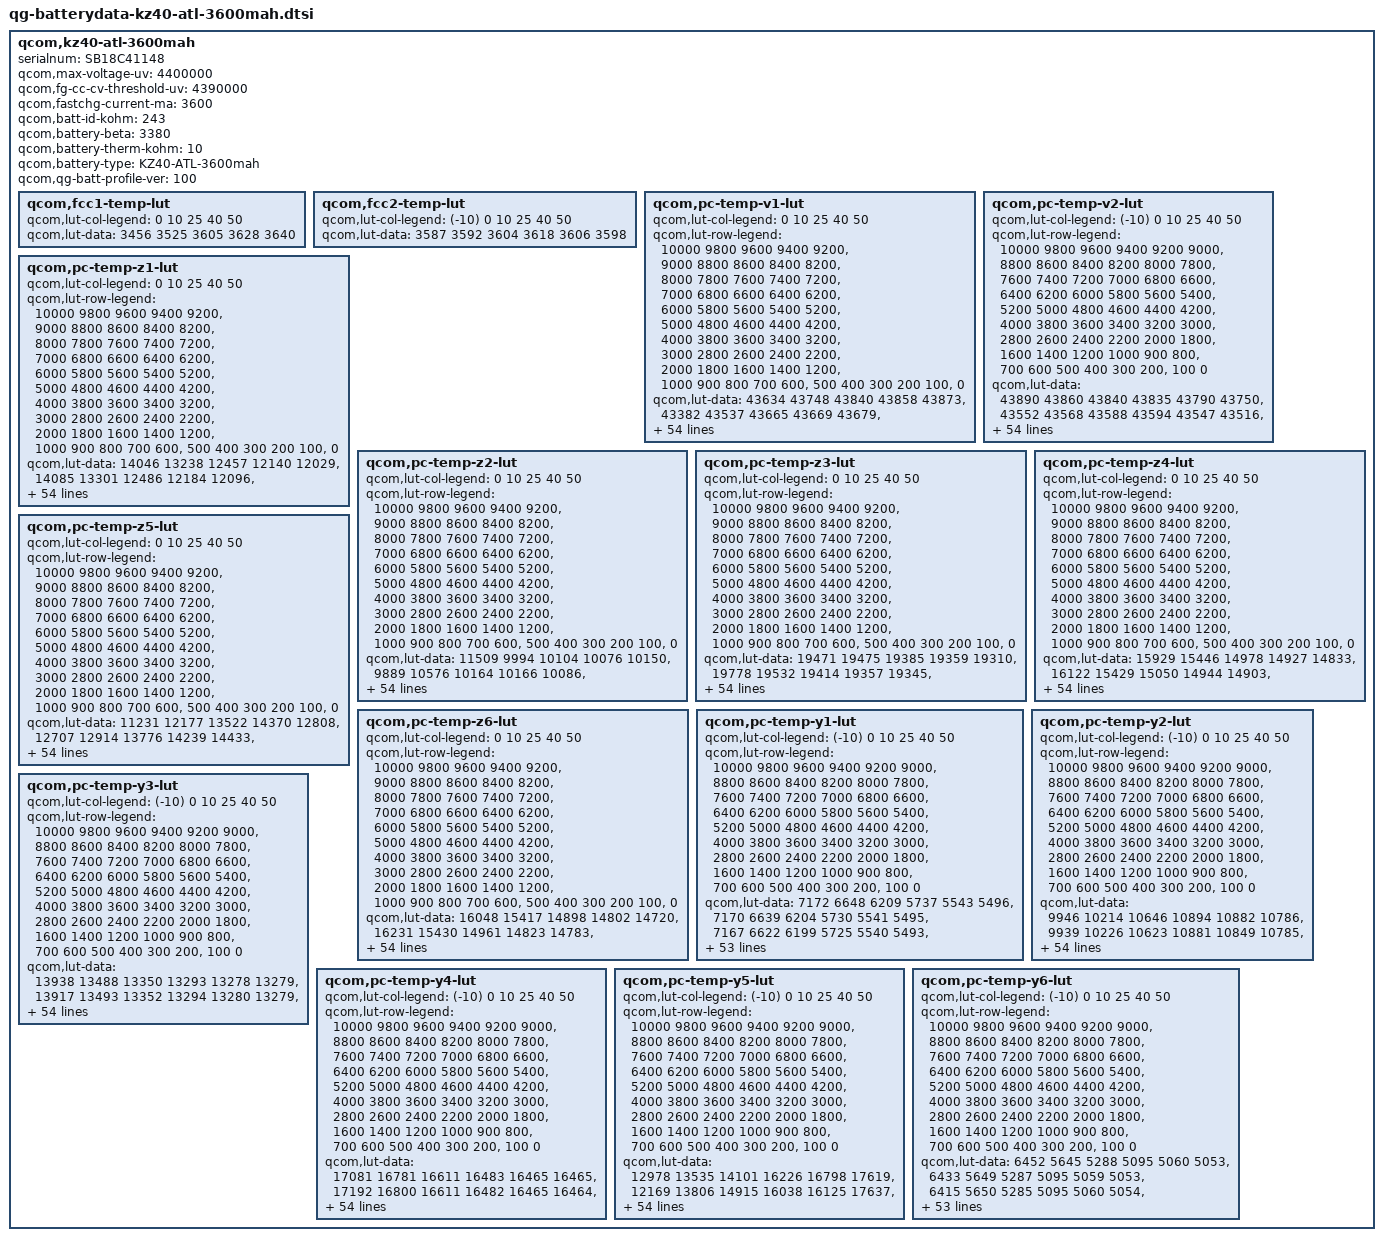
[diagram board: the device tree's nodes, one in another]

qcom,kz40-atl-3600mah {
    /* 3673330_Lenovo_KZ40moto_3600mAh_averaged_MasterSlave_Oct1st2018 */
    serialnum = "SB18C41148";
    qcom,max-voltage-uv = <4400000>;
    qcom,fg-cc-cv-threshold-uv = <4390000>;
    qcom,fastchg-current-ma = <3600>;
    qcom,batt-id-kohm = <243>;
    qcom,battery-beta = <3380>;
    qcom,battery-therm-kohm = <10>;
    qcom,battery-type = "KZ40-ATL-3600mah";
    qcom,qg-batt-profile-ver = <100>;

	qcom,fcc1-temp-lut {
		qcom,lut-col-legend = <0 10 25 40 50>;
		qcom,lut-data = <3456 3525 3605 3628 3640>;
	};

	qcom,fcc2-temp-lut {
		qcom,lut-col-legend = <(-10) 0 10 25 40 50>;
		qcom,lut-data = <3587 3592 3604 3618 3606 3598>;
	};

	qcom,pc-temp-v1-lut {
		qcom,lut-col-legend = <0 10 25 40 50>;
		qcom,lut-row-legend = <10000 9800 9600 9400 9200>,
			<9000 8800 8600 8400 8200>,
			<8000 7800 7600 7400 7200>,
			<7000 6800 6600 6400 6200>,
			<6000 5800 5600 5400 5200>,
			<5000 4800 4600 4400 4200>,
			<4000 3800 3600 3400 3200>,
			<3000 2800 2600 2400 2200>,
			<2000 1800 1600 1400 1200>,
			<1000 900 800 700 600>,
			<500 400 300 200 100>,
			<0>;
		qcom,lut-data = <43634 43748 43840 43858 43873>,
			<43382 43537 43665 43669 43679>,
			<43141 43311 43435 43460 43475>,
			<42905 43068 43204 43242 43263>,
			<42672 42824 42969 43015 43040>,
			<42441 42589 42731 42781 42809>,
			<42216 42357 42497 42548 42578>,
			<41995 42130 42264 42315 42346>,
			<41780 41908 42034 42083 42115>,
			<41569 41690 41806 41853 41885>,
			<41362 41475 41581 41625 41657>,
			<41163 41265 41364 41404 41434>,
			<40981 41065 41150 41186 41214>,
			<40802 40884 40943 40976 41002>,
			<40589 40699 40741 40772 40794>,
			<40322 40482 40542 40574 40593>,
			<40078 40240 40336 40378 40397>,
			<39909 40034 40134 40186 40208>,
			<39771 39880 39960 40007 40028>,
			<39637 39740 39822 39852 39867>,
			<39506 39583 39664 39689 39703>,
			<39376 39417 39408 39455 39485>,
			<39237 39237 39111 39166 39213>,
			<39090 39012 38924 38965 39004>,
			<38944 38791 38806 38845 38875>,
			<38798 38665 38706 38746 38766>,
			<38659 38585 38612 38643 38655>,
			<38551 38519 38526 38543 38548>,
			<38464 38456 38444 38450 38450>,
			<38394 38398 38366 38362 38359>,
			<38339 38343 38294 38281 38275>,
			<38294 38292 38227 38208 38199>,
			<38254 38243 38167 38141 38129>,
			<38219 38200 38115 38079 38062>,
			<38187 38160 38072 38023 38001>,
			<38155 38121 38030 37970 37940>,
			<38126 38085 37987 37917 37878>,
			<38090 38044 37943 37865 37814>,
			<38032 37979 37880 37797 37738>,
			<37953 37886 37788 37705 37644>,
			<37858 37783 37683 37601 37538>,
			<37736 37667 37571 37489 37423>,
			<37598 37534 37444 37362 37294>,
			<37442 37372 37288 37207 37138>,
			<37305 37234 37152 37073 37008>,
			<37216 37151 37066 36988 36932>,
			<37189 37126 37043 36966 36907>,
			<37170 37106 37028 36947 36889>,
			<37146 37085 37009 36928 36869>,
			<37095 37039 36958 36869 36802>,
			<36867 36801 36707 36601 36518>,
			<36419 36360 36271 36165 36083>,
			<35843 35787 35696 35594 35515>,
			<35057 35003 34912 34816 34743>,
			<33812 33769 33688 33612 33552>,
			<30000 30000 30000 30000 30000>;
	};

	qcom,pc-temp-v2-lut {
		qcom,lut-col-legend = <(-10) 0 10 25 40 50>;
		qcom,lut-row-legend = <10000 9800 9600 9400 9200 9000>,
			<8800 8600 8400 8200 8000 7800>,
			<7600 7400 7200 7000 6800 6600>,
			<6400 6200 6000 5800 5600 5400>,
			<5200 5000 4800 4600 4400 4200>,
			<4000 3800 3600 3400 3200 3000>,
			<2800 2600 2400 2200 2000 1800>,
			<1600 1400 1200 1000 900 800>,
			<700 600 500 400 300 200>,
			<100 0>;
		qcom,lut-data = <43890 43860 43840 43835 43790 43750>,
			<43552 43568 43588 43594 43547 43516>,
			<43236 43289 43339 43355 43307 43283>,
			<42942 43022 43093 43117 43071 43052>,
			<42668 42768 42850 42881 42840 42824>,
			<42413 42520 42609 42646 42609 42594>,
			<42184 42271 42369 42410 42377 42363>,
			<41967 42029 42132 42175 42144 42131>,
			<41727 41803 41902 41943 41914 41902>,
			<41456 41592 41676 41714 41686 41674>,
			<41228 41385 41456 41487 41461 41449>,
			<41091 41180 41241 41265 41239 41229>,
			<40974 40975 41031 41047 41021 41011>,
			<40768 40773 40829 40840 40813 40802>,
			<40397 40576 40635 40641 40613 40597>,
			<40032 40355 40433 40442 40417 40400>,
			<39765 40054 40207 40230 40217 40209>,
			<39532 39727 39970 40022 40022 40025>,
			<39328 39495 39741 39847 39847 39850>,
			<39149 39330 39515 39697 39693 39687>,
			<38983 39173 39304 39523 39519 39508>,
			<38818 38999 39111 39274 39277 39272>,
			<38662 38828 38935 39016 39021 39022>,
			<38525 38679 38783 38833 38837 38839>,
			<38401 38550 38649 38690 38697 38700>,
			<38296 38427 38527 38566 38574 38577>,
			<38215 38297 38416 38454 38462 38464>,
			<38148 38175 38313 38353 38361 38361>,
			<38087 38088 38219 38260 38268 38266>,
			<38033 38023 38132 38173 38183 38178>,
			<37982 37971 38052 38095 38105 38098>,
			<37932 37926 37974 38023 38036 38027>,
			<37883 37887 37904 37957 37970 37960>,
			<37834 37849 37847 37894 37902 37886>,
			<37786 37815 37800 37837 37833 37807>,
			<37737 37776 37756 37774 37755 37718>,
			<37683 37732 37714 37705 37659 37612>,
			<37624 37682 37671 37631 37555 37496>,
			<37555 37620 37615 37555 37468 37401>,
			<37474 37539 37543 37478 37390 37322>,
			<37387 37447 37460 37394 37308 37239>,
			<37298 37346 37356 37297 37213 37141>,
			<37207 37233 37236 37185 37105 37031>,
			<37117 37105 37095 37046 36971 36894>,
			<37030 36979 36972 36932 36865 36800>,
			<36940 36878 36904 36889 36824 36766>,
			<36891 36836 36880 36874 36812 36753>,
			<36839 36795 36854 36855 36799 36738>,
			<36777 36741 36813 36824 36770 36701>,
			<36664 36650 36717 36733 36678 36572>,
			<36432 36436 36427 36431 36372 36206>,
			<36007 35998 35916 35930 35889 35705>,
			<35381 35381 35246 35291 35261 35045>,
			<34489 34519 34318 34410 34410 34138>,
			<33116 33163 32958 33135 33145 32881>,
			<27998 27622 27822 27928 28920 29976>;
	};

	qcom,pc-temp-z1-lut {
		qcom,lut-col-legend = <0 10 25 40 50>;
		qcom,lut-row-legend = <10000 9800 9600 9400 9200>,
			<9000 8800 8600 8400 8200>,
			<8000 7800 7600 7400 7200>,
			<7000 6800 6600 6400 6200>,
			<6000 5800 5600 5400 5200>,
			<5000 4800 4600 4400 4200>,
			<4000 3800 3600 3400 3200>,
			<3000 2800 2600 2400 2200>,
			<2000 1800 1600 1400 1200>,
			<1000 900 800 700 600>,
			<500 400 300 200 100>,
			<0>;
		qcom,lut-data = <14046 13238 12457 12140 12029>,
			<14085 13301 12486 12184 12096>,
			<14085 13314 12512 12205 12116>,
			<14086 13298 12517 12212 12126>,
			<14090 13281 12508 12212 12130>,
			<14097 13264 12498 12212 12133>,
			<14097 13239 12489 12212 12136>,
			<14074 13223 12481 12211 12139>,
			<14043 13210 12477 12211 12142>,
			<14030 13200 12475 12213 12145>,
			<14023 13197 12474 12215 12148>,
			<14012 13194 12474 12216 12148>,
			<13980 13190 12474 12216 12149>,
			<13935 13166 12473 12216 12149>,
			<13904 13142 12470 12215 12149>,
			<13874 13133 12467 12214 12149>,
			<13852 13127 12465 12214 12149>,
			<13847 13125 12463 12214 12150>,
			<13852 13132 12463 12215 12151>,
			<13856 13140 12468 12216 12152>,
			<13861 13146 12473 12218 12153>,
			<13869 13154 12477 12219 12154>,
			<13884 13159 12480 12220 12154>,
			<13913 13162 12483 12221 12155>,
			<13931 13164 12486 12223 12157>,
			<13930 13167 12490 12227 12160>,
			<13924 13175 12496 12230 12163>,
			<13923 13182 12504 12234 12167>,
			<13936 13187 12510 12238 12170>,
			<13946 13192 12516 12243 12174>,
			<13946 13197 12522 12248 12177>,
			<13945 13205 12528 12252 12181>,
			<13944 13212 12535 12257 12184>,
			<13939 13218 12542 12261 12187>,
			<13934 13225 12550 12266 12192>,
			<13942 13233 12558 12271 12196>,
			<13968 13247 12565 12275 12198>,
			<13993 13262 12571 12278 12200>,
			<14011 13272 12579 12282 12203>,
			<14026 13281 12588 12286 12206>,
			<14032 13291 12596 12290 12210>,
			<14035 13310 12602 12294 12213>,
			<14038 13324 12608 12297 12216>,
			<14046 13334 12617 12300 12218>,
			<14056 13344 12627 12305 12220>,
			<14068 13349 12630 12307 12221>,
			<14071 13328 12628 12308 12222>,
			<14055 13328 12632 12309 12222>,
			<14053 13315 12632 12311 12225>,
			<14062 13334 12643 12315 12228>,
			<14105 13349 12649 12322 12233>,
			<14094 13376 12663 12329 12241>,
			<14117 13405 12676 12341 12251>,
			<14150 13452 12706 12357 12266>,
			<14150 13452 12706 12357 12266>,
			<14150 13452 12706 12357 12266>;
	};

	qcom,pc-temp-z2-lut {
		qcom,lut-col-legend = <0 10 25 40 50>;
		qcom,lut-row-legend = <10000 9800 9600 9400 9200>,
			<9000 8800 8600 8400 8200>,
			<8000 7800 7600 7400 7200>,
			<7000 6800 6600 6400 6200>,
			<6000 5800 5600 5400 5200>,
			<5000 4800 4600 4400 4200>,
			<4000 3800 3600 3400 3200>,
			<3000 2800 2600 2400 2200>,
			<2000 1800 1600 1400 1200>,
			<1000 900 800 700 600>,
			<500 400 300 200 100>,
			<0>;
		qcom,lut-data = <11509 9994 10104 10076 10150>,
			<9889 10576 10164 10166 10086>,
			<9883 10595 10194 10227 10081>,
			<9880 10236 10199 10251 10085>,
			<9876 9982 10188 10247 10122>,
			<9871 9963 10171 10239 10180>,
			<9870 9946 10150 10223 10194>,
			<9872 9934 10125 10190 10176>,
			<9874 9925 10112 10169 10149>,
			<9873 9919 10101 10163 10078>,
			<9869 9917 10096 10157 9990>,
			<9866 9915 10099 10128 9978>,
			<9876 9921 10105 10056 9995>,
			<9895 10005 10110 10024 10011>,
			<9890 10088 10117 10031 10021>,
			<9847 10069 10121 10039 10030>,
			<9812 10001 10123 10037 10035>,
			<9817 9972 10127 10027 10043>,
			<9834 9987 10128 10024 10051>,
			<9847 10008 10126 10045 10071>,
			<9856 10023 10123 10070 10094>,
			<9862 10037 10132 10076 10100>,
			<9866 10043 10145 10074 10101>,
			<9868 10039 10140 10074 10104>,
			<9870 10031 10111 10083 10125>,
			<9878 10032 10092 10092 10154>,
			<9890 10040 10119 10101 10180>,
			<9897 10047 10170 10121 10207>,
			<9902 10047 10191 10127 10212>,
			<9906 10045 10204 10120 10134>,
			<9910 10045 10209 10110 10049>,
			<9915 10049 10206 10084 10021>,
			<9919 10053 10201 10043 9986>,
			<9923 10056 10198 10031 9976>,
			<9928 10061 10195 10042 10008>,
			<9934 10065 10196 10060 10051>,
			<9942 10070 10208 10087 10088>,
			<9950 10076 10229 10125 10125>,
			<9957 10084 10251 10152 10157>,
			<9965 10095 10279 10171 10190>,
			<9970 10099 10295 10188 10209>,
			<9975 10098 10297 10209 10202>,
			<9983 10098 10298 10223 10189>,
			<10010 10106 10301 10217 10179>,
			<10191 10192 10315 10222 10174>,
			<10264 10251 10307 10203 10171>,
			<10287 10272 10283 10226 10158>,
			<10317 10301 10284 10238 10165>,
			<10318 10339 10291 10236 10208>,
			<10342 10342 10345 10324 10315>,
			<10272 10349 10444 10247 10094>,
			<10177 10344 10395 10117 9977>,
			<10034 10309 10362 10064 9923>,
			<9908 10217 10306 10023 9868>,
			<9908 10217 10306 10023 9868>,
			<9908 10217 10306 10023 9868>;
	};

	qcom,pc-temp-z3-lut {
		qcom,lut-col-legend = <0 10 25 40 50>;
		qcom,lut-row-legend = <10000 9800 9600 9400 9200>,
			<9000 8800 8600 8400 8200>,
			<8000 7800 7600 7400 7200>,
			<7000 6800 6600 6400 6200>,
			<6000 5800 5600 5400 5200>,
			<5000 4800 4600 4400 4200>,
			<4000 3800 3600 3400 3200>,
			<3000 2800 2600 2400 2200>,
			<2000 1800 1600 1400 1200>,
			<1000 900 800 700 600>,
			<500 400 300 200 100>,
			<0>;
		qcom,lut-data = <19471 19475 19385 19359 19310>,
			<19778 19532 19414 19357 19345>,
			<19865 19568 19451 19386 19366>,
			<19901 19631 19473 19410 19389>,
			<19903 19673 19487 19422 19402>,
			<19903 19675 19494 19431 19413>,
			<19901 19675 19493 19433 19416>,
			<19883 19672 19489 19434 19418>,
			<19861 19662 19485 19434 19419>,
			<19850 19652 19481 19430 19415>,
			<19834 19644 19475 19423 19407>,
			<19822 19634 19466 19415 19401>,
			<19818 19627 19454 19404 19395>,
			<19817 19624 19448 19397 19389>,
			<19820 19623 19444 19394 19385>,
			<19835 19619 19443 19392 19381>,
			<19843 19607 19443 19388 19378>,
			<19822 19596 19443 19383 19375>,
			<19784 19582 19441 19378 19372>,
			<19761 19569 19426 19373 19365>,
			<19750 19571 19415 19368 19358>,
			<19744 19586 19426 19370 19355>,
			<19749 19598 19447 19376 19353>,
			<19775 19605 19450 19378 19350>,
			<19796 19610 19438 19363 19341>,
			<19804 19610 19428 19349 19331>,
			<19810 19605 19426 19353 19342>,
			<19811 19599 19425 19364 19376>,
			<19806 19593 19427 19374 19394>,
			<19798 19587 19436 19389 19399>,
			<19789 19583 19446 19400 19400>,
			<19776 19581 19452 19401 19397>,
			<19764 19580 19457 19400 19390>,
			<19754 19577 19457 19397 19382>,
			<19744 19575 19449 19391 19373>,
			<19733 19572 19441 19385 19365>,
			<19720 19568 19436 19379 19361>,
			<19710 19564 19433 19373 19357>,
			<19705 19563 19430 19370 19355>,
			<19701 19561 19429 19367 19352>,
			<19696 19559 19427 19366 19350>,
			<19689 19551 19423 19366 19354>,
			<19680 19543 19419 19367 19361>,
			<19661 19538 19415 19367 19365>,
			<19570 19505 19405 19363 19363>,
			<19518 19471 19395 19357 19347>,
			<19472 19453 19386 19349 19341>,
			<19370 19438 19376 19349 19337>,
			<19358 19425 19374 19344 19328>,
			<19344 19431 19369 19331 19319>,
			<19370 19437 19355 19353 19359>,
			<19378 19422 19358 19365 19369>,
			<19371 19379 19364 19370 19370>,
			<19375 19374 19366 19370 19370>,
			<19375 19374 19366 19370 19370>,
			<19375 19374 19366 19370 19370>;
	};

	qcom,pc-temp-z4-lut {
		qcom,lut-col-legend = <0 10 25 40 50>;
		qcom,lut-row-legend = <10000 9800 9600 9400 9200>,
			<9000 8800 8600 8400 8200>,
			<8000 7800 7600 7400 7200>,
			<7000 6800 6600 6400 6200>,
			<6000 5800 5600 5400 5200>,
			<5000 4800 4600 4400 4200>,
			<4000 3800 3600 3400 3200>,
			<3000 2800 2600 2400 2200>,
			<2000 1800 1600 1400 1200>,
			<1000 900 800 700 600>,
			<500 400 300 200 100>,
			<0>;
		qcom,lut-data = <15929 15446 14978 14927 14833>,
			<16122 15429 15050 14944 14903>,
			<15959 15384 15043 14937 14900>,
			<15763 15270 15029 14927 14895>,
			<15619 15153 14973 14899 14877>,
			<15488 15072 14913 14861 14843>,
			<15385 15004 14876 14831 14815>,
			<15305 14952 14844 14806 14791>,
			<15239 14909 14815 14783 14771>,
			<15186 14876 14787 14762 14757>,
			<15144 14854 14767 14746 14745>,
			<15101 14836 14758 14739 14736>,
			<15040 14813 14752 14736 14729>,
			<14976 14772 14744 14731 14722>,
			<14940 14739 14734 14720 14714>,
			<14917 14742 14725 14708 14705>,
			<14899 14763 14714 14701 14698>,
			<14883 14770 14704 14696 14690>,
			<14866 14756 14699 14692 14686>,
			<14852 14740 14695 14686 14684>,
			<14841 14736 14693 14682 14683>,
			<14830 14737 14749 14723 14713>,
			<14817 14741 14849 14835 14819>,
			<14799 14798 14876 14877 14869>,
			<14791 14874 14875 14876 14867>,
			<14802 14886 14872 14874 14864>,
			<14822 14867 14860 14861 14843>,
			<14830 14845 14836 14829 14788>,
			<14831 14828 14812 14797 14749>,
			<14830 14810 14782 14763 14727>,
			<14825 14794 14756 14733 14710>,
			<14817 14778 14734 14715 14699>,
			<14808 14765 14716 14700 14690>,
			<14800 14753 14707 14694 14687>,
			<14792 14743 14702 14692 14687>,
			<14786 14735 14699 14691 14687>,
			<14781 14728 14697 14692 14688>,
			<14776 14723 14696 14695 14692>,
			<14769 14725 14698 14701 14698>,
			<14763 14729 14711 14717 14714>,
			<14761 14730 14719 14728 14726>,
			<14762 14729 14714 14722 14719>,
			<14762 14727 14709 14714 14708>,
			<14758 14724 14711 14718 14711>,
			<14760 14709 14703 14711 14704>,
			<14780 14711 14684 14691 14690>,
			<14825 14719 14680 14684 14683>,
			<14937 14729 14673 14662 14665>,
			<14946 14735 14664 14644 14647>,
			<14954 14726 14669 14656 14650>,
			<14925 14731 14714 14677 14661>,
			<14937 14759 14721 14676 14664>,
			<14959 14817 14720 14675 14667>,
			<14973 14831 14724 14680 14671>,
			<14973 14831 14724 14680 14671>,
			<14973 14831 14724 14680 14671>;
	};

	qcom,pc-temp-z5-lut {
		qcom,lut-col-legend = <0 10 25 40 50>;
		qcom,lut-row-legend = <10000 9800 9600 9400 9200>,
			<9000 8800 8600 8400 8200>,
			<8000 7800 7600 7400 7200>,
			<7000 6800 6600 6400 6200>,
			<6000 5800 5600 5400 5200>,
			<5000 4800 4600 4400 4200>,
			<4000 3800 3600 3400 3200>,
			<3000 2800 2600 2400 2200>,
			<2000 1800 1600 1400 1200>,
			<1000 900 800 700 600>,
			<500 400 300 200 100>,
			<0>;
		qcom,lut-data = <11231 12177 13522 14370 12808>,
			<12707 12914 13776 14239 14433>,
			<13281 13497 14988 15392 15453>,
			<13644 14521 15855 16457 16651>,
			<13888 15444 16499 17088 17517>,
			<14059 15999 16953 17615 18310>,
			<14193 16431 17180 18077 18972>,
			<14372 16708 17353 18476 19594>,
			<14530 17061 17674 18921 20067>,
			<14575 17320 18419 19625 20414>,
			<14614 17344 18919 20202 20668>,
			<14659 17411 18802 20048 20721>,
			<15074 17888 18575 19359 20713>,
			<15829 20352 18555 19067 20720>,
			<16450 22692 18874 19846 21128>,
			<17614 22480 19379 20819 21952>,
			<18445 21185 20641 21085 23044>,
			<18165 20849 22370 21214 24692>,
			<17418 21051 22632 21436 25593>,
			<17111 21263 21676 22197 25514>,
			<17372 23450 20967 23144 25156>,
			<17952 31017 26582 24119 24486>,
			<19840 36478 36520 25439 22748>,
			<25383 38455 37688 25570 20826>,
			<30510 39531 29654 20897 17565>,
			<34480 38312 22573 16154 14726>,
			<37903 33829 20327 15577 15057>,
			<38513 29692 18888 15585 16935>,
			<37107 27293 18760 16011 18569>,
			<35319 25497 19693 17612 20245>,
			<33481 25083 21141 19701 21979>,
			<30843 25232 24312 21764 23477>,
			<28865 25551 28418 24042 24945>,
			<27544 26234 29843 25752 25686>,
			<26428 27273 30332 27228 26044>,
			<25245 27791 30561 28035 26219>,
			<23718 28073 30639 27712 26108>,
			<22934 28244 30690 26752 25714>,
			<23317 28576 30523 25504 24923>,
			<23948 29438 29318 23395 22174>,
			<24023 29578 27788 21730 20050>,
			<23436 26888 26212 21131 20469>,
			<23139 25142 24662 20755 21287>,
			<22541 25114 23245 20329 21749>,
			<19618 24286 23021 20047 21676>,
			<16297 20089 22536 19529 18321>,
			<14658 17611 20499 18170 17420>,
			<11910 16038 18747 19791 18236>,
			<11747 15244 18829 21532 19340>,
			<11637 15778 18215 17825 17000>,
			<12077 16412 15009 17411 20681>,
			<12056 14850 14509 17596 19857>,
			<11815 12864 14516 17372 18437>,
			<11698 12549 14196 16272 16868>,
			<11698 12549 14196 16272 16868>,
			<11698 12549 14196 16272 16868>;
	};

	qcom,pc-temp-z6-lut {
		qcom,lut-col-legend = <0 10 25 40 50>;
		qcom,lut-row-legend = <10000 9800 9600 9400 9200>,
			<9000 8800 8600 8400 8200>,
			<8000 7800 7600 7400 7200>,
			<7000 6800 6600 6400 6200>,
			<6000 5800 5600 5400 5200>,
			<5000 4800 4600 4400 4200>,
			<4000 3800 3600 3400 3200>,
			<3000 2800 2600 2400 2200>,
			<2000 1800 1600 1400 1200>,
			<1000 900 800 700 600>,
			<500 400 300 200 100>,
			<0>;
		qcom,lut-data = <16048 15417 14898 14802 14720>,
			<16231 15430 14961 14823 14783>,
			<16168 15421 14974 14838 14799>,
			<16083 15385 14973 14843 14806>,
			<16006 15342 14955 14837 14804>,
			<15923 15302 14933 14827 14797>,
			<15851 15259 14915 14817 14790>,
			<15790 15224 14898 14807 14782>,
			<15737 15193 14882 14797 14774>,
			<15694 15167 14868 14786 14765>,
			<15660 15148 14856 14776 14757>,
			<15624 15133 14846 14768 14749>,
			<15579 15115 14837 14761 14743>,
			<15535 15089 14830 14754 14736>,
			<15507 15069 14823 14747 14730>,
			<15491 15065 14817 14740 14724>,
			<15475 15064 14812 14734 14719>,
			<15453 15061 14808 14730 14714>,
			<15428 15049 14802 14725 14710>,
			<15413 15036 14793 14719 14705>,
			<15406 15036 14788 14715 14700>,
			<15401 15045 14819 14734 14713>,
			<15403 15058 14874 14786 14757>,
			<15410 15089 14886 14805 14777>,
			<15420 15124 14882 14799 14773>,
			<15433 15129 14876 14791 14767>,
			<15446 15120 14870 14785 14763>,
			<15451 15110 14861 14779 14758>,
			<15451 15101 14854 14773 14754>,
			<15449 15092 14847 14767 14748>,
			<15444 15085 14842 14761 14741>,
			<15437 15080 14837 14755 14735>,
			<15430 15075 14833 14749 14728>,
			<15424 15071 14829 14744 14723>,
			<15419 15069 14824 14740 14717>,
			<15415 15067 14820 14736 14714>,
			<15412 15066 14818 14734 14712>,
			<15410 15065 14816 14732 14712>,
			<15412 15068 14817 14733 14712>,
			<15416 15075 14823 14738 14717>,
			<15420 15078 14827 14743 14722>,
			<15425 15077 14824 14741 14721>,
			<15426 15077 14821 14739 14721>,
			<15426 15079 14822 14741 14724>,
			<15394 15065 14816 14737 14720>,
			<15381 15052 14802 14725 14706>,
			<15377 15047 14796 14718 14700>,
			<15373 15044 14789 14709 14691>,
			<15373 15043 14784 14698 14678>,
			<15375 15045 14785 14697 14675>,
			<15385 15057 14800 14719 14702>,
			<15405 15069 14807 14728 14712>,
			<15427 15082 14814 14733 14717>,
			<15459 15102 14822 14739 14722>,
			<15459 15102 14822 14739 14722>,
			<15459 15102 14822 14739 14722>;
	};

	qcom,pc-temp-y1-lut {
		qcom,lut-col-legend = <(-10) 0 10 25 40 50>;
		qcom,lut-row-legend = <10000 9800 9600 9400 9200 9000>,
			<8800 8600 8400 8200 8000 7800>,
			<7600 7400 7200 7000 6800 6600>,
			<6400 6200 6000 5800 5600 5400>,
			<5200 5000 4800 4600 4400 4200>,
			<4000 3800 3600 3400 3200 3000>,
			<2800 2600 2400 2200 2000 1800>,
			<1600 1400 1200 1000 900 800>,
			<700 600 500 400 300 200>,
			<100 0>;
		qcom,lut-data = <7172 6648 6209 5737 5543 5496>,
			<7170 6639 6204 5730 5541 5495>,
			<7167 6622 6199 5725 5540 5493>,
			<7165 6604 6194 5719 5538 5491>,
			<7163 6590 6189 5714 5537 5490>,
			<7161 6584 6183 5710 5535 5489>,
			<7160 6585 6178 5705 5534 5487>,
			<7159 6587 6172 5702 5532 5486>,
			<7157 6586 6165 5699 5531 5486>,
			<7147 6584 6156 5696 5530 5486>,
			<7141 6583 6151 5694 5530 5486>,
			<7147 6581 6148 5692 5528 5486>,
			<7156 6580 6144 5690 5527 5485>,
			<7156 6580 6142 5688 5527 5485>,
			<7149 6583 6137 5688 5527 5485>,
			<7144 6587 6134 5687 5527 5485>,
			<7154 6594 6137 5688 5529 5486>,
			<7171 6602 6141 5690 5530 5486>,
			<7182 6604 6142 5691 5531 5487>,
			<7186 6605 6146 5693 5531 5487>,
			<7186 6604 6148 5695 5531 5487>,
			<7170 6602 6146 5697 5531 5487>,
			<7144 6598 6144 5699 5532 5487>,
			<7139 6598 6143 5702 5533 5488>,
			<7152 6602 6145 5704 5535 5489>,
			<7161 6606 6146 5707 5537 5491>,
			<7159 6608 6150 5710 5539 5492>,
			<7153 6611 6155 5714 5542 5494>,
			<7147 6611 6158 5719 5544 5496>,
			<7140 6605 6161 5724 5546 5498>,
			<7132 6599 6165 5729 5548 5501>,
			<7126 6592 6172 5734 5551 5503>,
			<7120 6585 6179 5739 5554 5505>,
			<7117 6585 6180 5743 5557 5507>,
			<7117 6593 6180 5747 5560 5509>,
			<7116 6599 6180 5751 5562 5511>,
			<7110 6594 6188 5754 5565 5512>,
			<7102 6586 6199 5756 5566 5513>,
			<7098 6584 6200 5758 5567 5515>,
			<7097 6586 6196 5759 5567 5516>,
			<7097 6589 6194 5761 5568 5517>,
			<7094 6588 6198 5763 5570 5517>,
			<7088 6588 6203 5767 5572 5519>,
			<7085 6594 6206 5773 5574 5520>,
			<7087 6591 6216 5782 5577 5524>,
			<7140 6584 6231 5787 5581 5526>,
			<7117 6600 6238 5788 5582 5527>,
			<7122 6595 6227 5789 5581 5526>,
			<7124 6618 6233 5791 5582 5527>,
			<7123 6621 6232 5791 5582 5529>,
			<7114 6591 6233 5797 5584 5532>,
			<7124 6612 6251 5808 5590 5537>,
			<7131 6624 6269 5823 5598 5544>,
			<7199 6630 6279 5845 5609 5554>,
			<7199 6630 6279 5845 5609 5554>,
			<7199 6630 6279 5845 5609 5554>;
	};

	qcom,pc-temp-y2-lut {
		qcom,lut-col-legend = <(-10) 0 10 25 40 50>;
		qcom,lut-row-legend = <10000 9800 9600 9400 9200 9000>,
			<8800 8600 8400 8200 8000 7800>,
			<7600 7400 7200 7000 6800 6600>,
			<6400 6200 6000 5800 5600 5400>,
			<5200 5000 4800 4600 4400 4200>,
			<4000 3800 3600 3400 3200 3000>,
			<2800 2600 2400 2200 2000 1800>,
			<1600 1400 1200 1000 900 800>,
			<700 600 500 400 300 200>,
			<100 0>;
		qcom,lut-data = <9946 10214 10646 10894 10882 10786>,
			<9939 10226 10623 10881 10849 10785>,
			<9942 10238 10602 10866 10815 10779>,
			<9953 10250 10582 10851 10781 10768>,
			<9970 10262 10564 10835 10753 10754>,
			<9991 10274 10550 10819 10731 10737>,
			<10015 10288 10537 10798 10717 10713>,
			<10047 10300 10527 10779 10704 10688>,
			<10108 10304 10526 10776 10693 10674>,
			<10242 10304 10529 10779 10681 10665>,
			<10323 10305 10534 10782 10673 10658>,
			<10300 10371 10541 10785 10673 10651>,
			<10262 10481 10552 10787 10676 10642>,
			<10264 10522 10574 10786 10679 10639>,
			<10339 10541 10623 10778 10687 10634>,
			<10418 10549 10668 10774 10701 10634>,
			<10473 10548 10702 10801 10748 10648>,
			<10517 10546 10727 10853 10823 10679>,
			<10459 10549 10730 10910 10899 10743>,
			<10036 10575 10728 10981 10997 10901>,
			<9717 10605 10726 11011 11045 10996>,
			<9699 10631 10737 10967 10967 10956>,
			<9691 10656 10759 10910 10854 10889>,
			<9684 10672 10779 10902 10843 10863>,
			<9677 10682 10801 10918 10878 10850>,
			<9672 10690 10819 10933 10904 10845>,
			<9670 10696 10832 10945 10913 10865>,
			<9668 10701 10842 10959 10920 10902>,
			<9667 10702 10851 10975 10931 10928>,
			<9666 10703 10861 10996 10944 10954>,
			<9664 10702 10867 11018 10960 10973>,
			<9663 10687 10868 11052 10984 10990>,
			<9662 10656 10868 11079 11011 11007>,
			<9661 10632 10868 11080 11031 11003>,
			<9661 10613 10865 11075 11053 10971>,
			<9660 10588 10861 11068 11061 10949>,
			<9659 10438 10851 11060 11022 10952>,
			<9659 10190 10836 11050 10965 10958>,
			<9658 10071 10818 11039 10944 10951>,
			<9658 9848 10794 11025 10933 10914>,
			<9657 9687 10768 11013 10928 10886>,
			<9657 9675 10743 11003 10919 10896>,
			<9656 9669 10711 10999 10915 10906>,
			<9656 9664 10657 10969 10918 10884>,
			<9656 9661 10585 10934 10875 10804>,
			<9655 9659 10536 10932 10793 10674>,
			<9655 9659 10506 10928 10781 10663>,
			<9655 9658 10488 10949 10830 10669>,
			<9655 9656 10475 10955 10857 10669>,
			<9654 9655 10434 10964 10843 10643>,
			<9654 9655 10363 10928 10762 10621>,
			<9653 9654 10259 10875 10692 10554>,
			<9652 9653 9958 10833 10631 10490>,
			<9650 9652 9723 10741 10583 10397>,
			<9650 9652 9723 10741 10583 10397>,
			<9650 9652 9723 10741 10583 10397>;
	};

	qcom,pc-temp-y3-lut {
		qcom,lut-col-legend = <(-10) 0 10 25 40 50>;
		qcom,lut-row-legend = <10000 9800 9600 9400 9200 9000>,
			<8800 8600 8400 8200 8000 7800>,
			<7600 7400 7200 7000 6800 6600>,
			<6400 6200 6000 5800 5600 5400>,
			<5200 5000 4800 4600 4400 4200>,
			<4000 3800 3600 3400 3200 3000>,
			<2800 2600 2400 2200 2000 1800>,
			<1600 1400 1200 1000 900 800>,
			<700 600 500 400 300 200>,
			<100 0>;
		qcom,lut-data = <13938 13488 13350 13293 13278 13279>,
			<13917 13493 13352 13294 13280 13279>,
			<13892 13497 13355 13295 13281 13280>,
			<13866 13499 13359 13296 13282 13281>,
			<13845 13500 13362 13297 13284 13282>,
			<13831 13500 13363 13298 13285 13283>,
			<13825 13499 13364 13299 13286 13285>,
			<13820 13496 13364 13300 13289 13286>,
			<13805 13498 13365 13300 13290 13287>,
			<13758 13511 13368 13301 13291 13288>,
			<13703 13520 13369 13301 13292 13288>,
			<13637 13511 13370 13304 13292 13289>,
			<13572 13493 13370 13308 13293 13290>,
			<13561 13477 13370 13310 13293 13290>,
			<13573 13463 13372 13312 13295 13290>,
			<13582 13452 13373 13312 13297 13290>,
			<13553 13444 13371 13310 13297 13292>,
			<13500 13438 13367 13308 13296 13295>,
			<13479 13431 13363 13308 13297 13296>,
			<13470 13422 13356 13312 13297 13296>,
			<13466 13413 13350 13313 13298 13296>,
			<13469 13403 13343 13309 13293 13291>,
			<13474 13394 13337 13302 13286 13282>,
			<13472 13387 13335 13298 13284 13281>,
			<13453 13381 13333 13295 13284 13281>,
			<13435 13374 13332 13294 13284 13281>,
			<13433 13364 13331 13294 13283 13281>,
			<13436 13353 13330 13294 13283 13281>,
			<13446 13349 13329 13294 13282 13280>,
			<13471 13347 13328 13294 13282 13279>,
			<13501 13346 13327 13295 13282 13278>,
			<13524 13350 13327 13296 13283 13279>,
			<13548 13356 13326 13297 13283 13279>,
			<13576 13361 13326 13297 13284 13280>,
			<13608 13366 13327 13298 13285 13281>,
			<13645 13370 13327 13298 13285 13281>,
			<13685 13377 13328 13297 13284 13280>,
			<13730 13385 13330 13296 13283 13279>,
			<13776 13394 13331 13295 13282 13279>,
			<13824 13404 13331 13294 13283 13281>,
			<13875 13417 13332 13293 13283 13282>,
			<13934 13436 13333 13294 13283 13283>,
			<14000 13467 13334 13294 13283 13283>,
			<14069 13515 13336 13292 13283 13279>,
			<14151 13598 13337 13293 13282 13279>,
			<14176 13641 13337 13294 13286 13288>,
			<14206 13689 13343 13297 13290 13290>,
			<14298 13774 13351 13300 13297 13294>,
			<14395 13858 13362 13308 13299 13295>,
			<14503 13956 13371 13311 13298 13292>,
			<14642 14062 13375 13304 13293 13290>,
			<14835 14213 13385 13303 13294 13292>,
			<15145 14445 13416 13312 13298 13295>,
			<16072 14703 13507 13321 13305 13303>,
			<16072 14703 13507 13321 13305 13303>,
			<16072 14703 13507 13321 13305 13303>;
	};

	qcom,pc-temp-y4-lut {
		qcom,lut-col-legend = <(-10) 0 10 25 40 50>;
		qcom,lut-row-legend = <10000 9800 9600 9400 9200 9000>,
			<8800 8600 8400 8200 8000 7800>,
			<7600 7400 7200 7000 6800 6600>,
			<6400 6200 6000 5800 5600 5400>,
			<5200 5000 4800 4600 4400 4200>,
			<4000 3800 3600 3400 3200 3000>,
			<2800 2600 2400 2200 2000 1800>,
			<1600 1400 1200 1000 900 800>,
			<700 600 500 400 300 200>,
			<100 0>;
		qcom,lut-data = <17081 16781 16611 16483 16465 16465>,
			<17192 16800 16611 16482 16465 16464>,
			<17272 16827 16611 16482 16465 16464>,
			<17324 16854 16611 16483 16466 16463>,
			<17352 16877 16612 16485 16467 16463>,
			<17361 16890 16614 16486 16467 16463>,
			<17335 16895 16616 16489 16468 16464>,
			<17292 16897 16619 16494 16469 16464>,
			<17278 16897 16624 16500 16472 16466>,
			<17287 16893 16633 16508 16476 16470>,
			<17312 16890 16644 16516 16481 16475>,
			<17478 16938 16656 16521 16487 16479>,
			<17727 17028 16673 16526 16494 16483>,
			<17725 17090 16706 16535 16501 16489>,
			<17376 17142 16773 16552 16510 16498>,
			<17088 17167 16812 16572 16519 16506>,
			<17014 17039 16805 16598 16531 16514>,
			<16969 16826 16790 16626 16545 16521>,
			<16963 16772 16758 16652 16568 16537>,
			<16976 16767 16676 16679 16609 16569>,
			<16985 16762 16610 16689 16630 16588>,
			<16942 16741 16579 16612 16580 16553>,
			<16863 16708 16558 16510 16502 16496>,
			<16835 16686 16549 16486 16478 16476>,
			<16830 16671 16543 16478 16469 16469>,
			<16828 16655 16541 16476 16466 16467>,
			<16832 16627 16541 16479 16469 16469>,
			<16838 16599 16543 16484 16475 16473>,
			<16837 16593 16544 16489 16483 16480>,
			<16825 16597 16546 16496 16493 16490>,
			<16816 16600 16546 16503 16505 16502>,
			<16816 16602 16541 16512 16520 16516>,
			<16819 16604 16534 16521 16533 16529>,
			<16820 16608 16534 16529 16535 16530>,
			<16822 16617 16540 16536 16535 16528>,
			<16823 16630 16547 16538 16532 16524>,
			<16824 16652 16557 16526 16512 16508>,
			<16826 16682 16567 16510 16485 16485>,
			<16826 16703 16573 16501 16482 16482>,
			<16825 16725 16577 16495 16484 16484>,
			<16822 16737 16579 16494 16486 16486>,
			<16817 16735 16578 16497 16488 16487>,
			<16811 16730 16576 16497 16489 16487>,
			<16820 16724 16573 16491 16472 16468>,
			<16839 16728 16574 16479 16464 16460>,
			<16837 16732 16570 16485 16472 16474>,
			<16844 16750 16589 16501 16489 16503>,
			<16873 16787 16620 16522 16516 16539>,
			<16907 16840 16667 16555 16555 16575>,
			<16934 16908 16709 16570 16564 16560>,
			<16923 16934 16692 16522 16491 16477>,
			<16890 16897 16677 16511 16478 16477>,
			<16896 16913 16744 16530 16485 16482>,
			<17124 16955 16850 16586 16519 16523>,
			<17124 16955 16850 16586 16519 16523>,
			<17124 16955 16850 16586 16519 16523>;
	};

	qcom,pc-temp-y5-lut {
		qcom,lut-col-legend = <(-10) 0 10 25 40 50>;
		qcom,lut-row-legend = <10000 9800 9600 9400 9200 9000>,
			<8800 8600 8400 8200 8000 7800>,
			<7600 7400 7200 7000 6800 6600>,
			<6400 6200 6000 5800 5600 5400>,
			<5200 5000 4800 4600 4400 4200>,
			<4000 3800 3600 3400 3200 3000>,
			<2800 2600 2400 2200 2000 1800>,
			<1600 1400 1200 1000 900 800>,
			<700 600 500 400 300 200>,
			<100 0>;
		qcom,lut-data = <12978 13535 14101 16226 16798 17619>,
			<12169 13806 14915 16038 16125 17637>,
			<11841 14085 15416 15820 15827 17644>,
			<11878 14333 15680 15586 15775 17644>,
			<12166 14511 15783 15354 15840 17642>,
			<12588 14581 15800 15138 15894 17643>,
			<13473 14526 15574 14916 16136 17742>,
			<14493 14439 15181 14654 16450 17819>,
			<14523 14678 14963 14310 16339 17530>,
			<13559 16098 14782 13833 15951 16751>,
			<12897 17052 14663 13602 15513 16044>,
			<13184 15856 14526 13821 15036 15662>,
			<13904 13919 14364 14126 14569 15337>,
			<15156 13960 14344 14056 14288 14896>,
			<18243 16496 14469 13574 14070 14277>,
			<20246 18234 14698 13285 13986 13951>,
			<18724 18129 16504 13244 13770 14043>,
			<15822 17916 19050 13236 13443 14218>,
			<14381 17794 19700 13950 13494 14355>,
			<13595 17733 19849 16851 14051 14562>,
			<13203 17707 19853 18999 14831 14841>,
			<13204 17564 18909 19993 16256 15773>,
			<13274 17336 17592 20657 17808 17111>,
			<13117 17393 17388 20199 18285 17781>,
			<12267 18045 17486 18303 18452 18194>,
			<11574 18512 17573 17171 18443 18366>,
			<11430 17260 17527 16904 17669 17755>,
			<11340 15029 17441 16757 16522 16589>,
			<11361 14235 17535 16793 16015 15695>,
			<11590 13933 17896 17124 15665 14826>,
			<11804 13794 18216 17512 15537 14403>,
			<11872 14174 18430 18082 15743 14509>,
			<11916 14996 18587 18766 16173 14771>,
			<11993 15658 18573 19364 16822 15255>,
			<12202 16252 18420 19954 17917 16369>,
			<12414 16749 18332 20259 18452 17122>,
			<12568 16651 18516 20321 18385 17247>,
			<12703 16021 18774 20246 18231 17330>,
			<12711 15614 18710 19743 17938 17434>,
			<12493 14190 18214 18554 17341 17526>,
			<12283 13155 17789 17707 16887 17565>,
			<12234 13119 17598 17233 16533 17629>,
			<12201 13051 17389 17014 16349 17594>,
			<12088 12842 16994 16634 17679 16646>,
			<12074 12610 16215 16799 16522 15757>,
			<12186 12568 15853 16374 15647 16741>,
			<12199 12690 15846 15655 15773 15701>,
			<12352 13006 15894 15622 16518 15379>,
			<12675 13139 16058 16199 15956 14798>,
			<12815 13217 16077 16687 15439 14353>,
			<12889 13043 15961 16379 16103 16927>,
			<12552 12831 16001 16568 17680 16910>,
			<12307 12634 14551 19197 18525 17737>,
			<11568 12324 13423 20782 22034 22081>,
			<11568 12324 13423 20782 22034 22081>,
			<11568 12324 13423 20782 22034 22081>;
	};

	qcom,pc-temp-y6-lut {
		qcom,lut-col-legend = <(-10) 0 10 25 40 50>;
		qcom,lut-row-legend = <10000 9800 9600 9400 9200 9000>,
			<8800 8600 8400 8200 8000 7800>,
			<7600 7400 7200 7000 6800 6600>,
			<6400 6200 6000 5800 5600 5400>,
			<5200 5000 4800 4600 4400 4200>,
			<4000 3800 3600 3400 3200 3000>,
			<2800 2600 2400 2200 2000 1800>,
			<1600 1400 1200 1000 900 800>,
			<700 600 500 400 300 200>,
			<100 0>;
		qcom,lut-data = <6452 5645 5288 5095 5060 5053>,
			<6433 5649 5287 5095 5059 5053>,
			<6415 5650 5285 5095 5060 5054>,
			<6397 5648 5283 5095 5060 5054>,
			<6378 5646 5281 5096 5061 5055>,
			<6360 5642 5278 5097 5063 5056>,
			<6343 5635 5275 5098 5064 5057>,
			<6326 5627 5272 5099 5066 5059>,
			<6301 5626 5272 5101 5068 5060>,
			<6263 5626 5273 5103 5069 5061>,
			<6242 5627 5275 5106 5071 5063>,
			<6254 5630 5277 5109 5073 5065>,
			<6274 5636 5279 5113 5076 5067>,
			<6267 5640 5286 5118 5078 5069>,
			<6195 5645 5304 5123 5082 5071>,
			<6126 5647 5315 5129 5086 5074>,
			<6093 5613 5312 5135 5090 5077>,
			<6068 5554 5305 5141 5093 5081>,
			<6055 5534 5294 5149 5100 5087>,
			<6046 5528 5266 5159 5112 5096>,
			<6039 5523 5242 5163 5118 5101>,
			<6030 5513 5228 5138 5100 5087>,
			<6022 5502 5218 5103 5072 5064>,
			<6021 5499 5216 5094 5064 5057>,
			<6024 5499 5214 5090 5061 5055>,
			<6029 5499 5214 5088 5060 5054>,
			<6041 5497 5215 5089 5061 5055>,
			<6062 5494 5216 5091 5062 5056>,
			<6083 5495 5218 5094 5064 5058>,
			<6105 5508 5221 5097 5067 5060>,
			<6129 5526 5223 5100 5071 5063>,
			<6153 5544 5224 5104 5076 5067>,
			<6180 5564 5225 5108 5081 5072>,
			<6209 5587 5228 5111 5082 5073>,
			<6241 5612 5233 5114 5083 5073>,
			<6276 5639 5239 5115 5082 5072>,
			<6312 5669 5247 5111 5076 5067>,
			<6351 5701 5255 5107 5067 5060>,
			<6391 5736 5263 5104 5066 5059>,
			<6432 5774 5270 5102 5067 5061>,
			<6474 5816 5278 5101 5068 5063>,
			<6520 5867 5288 5103 5069 5064>,
			<6569 5927 5301 5104 5070 5064>,
			<6627 6000 5317 5102 5065 5056>,
			<6701 6099 5339 5100 5063 5055>,
			<6736 6150 5343 5104 5068 5065>,
			<6769 6203 5364 5111 5076 5075>,
			<6847 6287 5396 5120 5089 5088>,
			<6935 6379 5434 5135 5101 5099>,
			<7029 6485 5474 5141 5104 5093>,
			<7140 6587 5497 5124 5079 5069>,
			<7293 6708 5548 5121 5077 5070>,
			<7550 6901 5663 5137 5082 5076>,
			<8408 7123 5834 5163 5100 5095>,
			<8408 7123 5834 5163 5100 5095>,
			<8408 7123 5834 5163 5100 5095>;
	};

};
